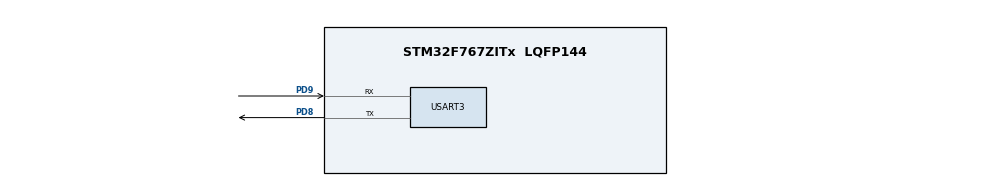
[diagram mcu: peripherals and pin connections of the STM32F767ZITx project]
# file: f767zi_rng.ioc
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CORTEX_M7.default_mode_Activation=1
Mcu.Family=STM32F7
Mcu.Name=STM32F767ZITx
Mcu.Package=LQFP144
NVIC.PriorityGroup=NVIC_PRIORITYGROUP_4
PA13.Mode=Serial_Wire
PA13.Signal=SYS_JTMS-SWDIO
PA14.Mode=Serial_Wire
PA14.Signal=SYS_JTCK-SWCLK
PD8.Mode=Asynchronous
PD8.Signal=USART3_TX
PD9.Mode=Asynchronous
PD9.Signal=USART3_RX
PH0/OSC_IN.Mode=HSE-External-Oscillator
PH0/OSC_IN.Signal=RCC_OSC_IN
PH1/OSC_OUT.Mode=HSE-External-Oscillator
PH1/OSC_OUT.Signal=RCC_OSC_OUT
ProjectManager.HeapSize=0x200
ProjectManager.StackSize=0x400
ProjectManager.TargetToolchain=STM32CubeIDE
RCC.HSE_VALUE=25000000
RCC.HSI_VALUE=16000000
RCC.LSE_VALUE=32768
RCC.PLLM=8
RCC.PLLN=96
RCC.PLLQ=4
RCC.USBFreq_Value=48000000
RCC.VCOOutputFreq_Value=192000000
USART3.VirtualMode-Asynchronous=VM_ASYNC
VP_RNG_VS_RNG.Mode=RNG_Activate
board=custom

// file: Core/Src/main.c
/* USER CODE BEGIN Header */
/**
  ******************************************************************************
  * @file           : main.c
  * @brief          : Main program body
  ******************************************************************************
  * @attention
  *
  * Copyright (c) 2025 STMicroelectronics.
  * All rights reserved.
  *
  * This software is licensed under terms that can be found in the LICENSE file
  * in the root directory of this software component.
  * If no LICENSE file comes with this software, it is provided AS-IS.
  *
  ******************************************************************************
  */
/* USER CODE END Header */
#include "main.h"

/* USER CODE BEGIN Includes */
#include <stdio.h>
#include <stdbool.h>
#include "trng.h"
/* USER CODE END Includes */

RNG_HandleTypeDef hrng;

UART_HandleTypeDef huart3;

void SystemClock_Config(void);
static void MPU_Config(void);
static void MX_GPIO_Init(void);
static void MX_USART3_UART_Init(void);
static void MX_RNG_Init(void);

/* USER CODE BEGIN 0 */

/* redirect printf to uart3
 fd == file descriptor. 1 = stdout, 2 stderr
 ptr == pointer to the data being sent
 len == length of the data (in bytes)
*/
int _write(int fd, char* ptr, int len) {
 HAL_StatusTypeDef hstatus;

 if (fd == 1 || fd == 2) {
   hstatus = HAL_UART_Transmit(&huart3, (uint8_t *) ptr, len, HAL_MAX_DELAY);
   if (hstatus == HAL_OK)
     return len;
   else
     return -1;
 }
 return -1;
}

/* USER CODE END 0 */

int main(void)
{

  /* MPU Configuration--------------------------------------------------------*/
  MPU_Config();

  /* MCU Configuration--------------------------------------------------------*/

  /* Reset of all peripherals, Initializes the Flash interface and the Systick. */
  HAL_Init();

  /* Configure the system clock */
  SystemClock_Config();

  /* Initialize all configured peripherals */
  MX_GPIO_Init();
  MX_USART3_UART_Init();
  MX_RNG_Init();
  /* USER CODE BEGIN 2 */
  printf("Starting RNG code...\r\n");
  trng_init();
  /* USER CODE END 2 */

  /* Infinite loop */
  /* USER CODE BEGIN WHILE */
  uint32_t now = 0,next_tick=1000;
  while (1)
  {
	  now = uwTick;
	  if(now >= next_tick){
		  printf("Tick %lu. Random value = %lu \r\n",now/1000,trng_get());
		  next_tick = now+1000;
	  }

  }
    /* USER CODE END WHILE */

}

void SystemClock_Config(void)
{
  RCC_OscInitTypeDef RCC_OscInitStruct = {0};
  RCC_ClkInitTypeDef RCC_ClkInitStruct = {0};

  /** Configure the main internal regulator output voltage
  */
  __HAL_RCC_PWR_CLK_ENABLE();
  __HAL_PWR_VOLTAGESCALING_CONFIG(PWR_REGULATOR_VOLTAGE_SCALE3);

  /** Initializes the RCC Oscillators according to the specified parameters
  * in the RCC_OscInitTypeDef structure.
  */
  RCC_OscInitStruct.OscillatorType = RCC_OSCILLATORTYPE_HSI;
  RCC_OscInitStruct.HSIState = RCC_HSI_ON;
  RCC_OscInitStruct.HSICalibrationValue = RCC_HSICALIBRATION_DEFAULT;
  RCC_OscInitStruct.PLL.PLLState = RCC_PLL_ON;
  RCC_OscInitStruct.PLL.PLLSource = RCC_PLLSOURCE_HSI;
  RCC_OscInitStruct.PLL.PLLM = 8;
  RCC_OscInitStruct.PLL.PLLN = 96;
  RCC_OscInitStruct.PLL.PLLP = RCC_PLLP_DIV2;
  RCC_OscInitStruct.PLL.PLLQ = 4;
  RCC_OscInitStruct.PLL.PLLR = 2;
  if (HAL_RCC_OscConfig(&RCC_OscInitStruct) != HAL_OK)
  {
    Error_Handler();
  }

  /** Initializes the CPU, AHB and APB buses clocks
  */
  RCC_ClkInitStruct.ClockType = RCC_CLOCKTYPE_HCLK|RCC_CLOCKTYPE_SYSCLK
                              |RCC_CLOCKTYPE_PCLK1|RCC_CLOCKTYPE_PCLK2;
  RCC_ClkInitStruct.SYSCLKSource = RCC_SYSCLKSOURCE_HSI;
  RCC_ClkInitStruct.AHBCLKDivider = RCC_SYSCLK_DIV1;
  RCC_ClkInitStruct.APB1CLKDivider = RCC_HCLK_DIV1;
  RCC_ClkInitStruct.APB2CLKDivider = RCC_HCLK_DIV1;

  if (HAL_RCC_ClockConfig(&RCC_ClkInitStruct, FLASH_LATENCY_0) != HAL_OK)
  {
    Error_Handler();
  }
}

static void MX_RNG_Init(void)
{

  hrng.Instance = RNG;
  if (HAL_RNG_Init(&hrng) != HAL_OK)
  {
    Error_Handler();
  }

}

static void MX_USART3_UART_Init(void)
{

  huart3.Instance = USART3;
  huart3.Init.BaudRate = 115200;
  huart3.Init.WordLength = UART_WORDLENGTH_8B;
  huart3.Init.StopBits = UART_STOPBITS_1;
  huart3.Init.Parity = UART_PARITY_NONE;
  huart3.Init.Mode = UART_MODE_TX_RX;
  huart3.Init.HwFlowCtl = UART_HWCONTROL_NONE;
  huart3.Init.OverSampling = UART_OVERSAMPLING_16;
  huart3.Init.OneBitSampling = UART_ONE_BIT_SAMPLE_DISABLE;
  huart3.AdvancedInit.AdvFeatureInit = UART_ADVFEATURE_NO_INIT;
  if (HAL_UART_Init(&huart3) != HAL_OK)
  {
    Error_Handler();
  }

}

static void MX_GPIO_Init(void)
{

  /* GPIO Ports Clock Enable */
  __HAL_RCC_GPIOH_CLK_ENABLE();
  __HAL_RCC_GPIOD_CLK_ENABLE();
  __HAL_RCC_GPIOA_CLK_ENABLE();

}

 /* MPU Configuration */

void MPU_Config(void)
{
  MPU_Region_InitTypeDef MPU_InitStruct = {0};

  /* Disables the MPU */
  HAL_MPU_Disable();

  /** Initializes and configures the Region and the memory to be protected
  */
  MPU_InitStruct.Enable = MPU_REGION_ENABLE;
  MPU_InitStruct.Number = MPU_REGION_NUMBER0;
  MPU_InitStruct.BaseAddress = 0x0;
  MPU_InitStruct.Size = MPU_REGION_SIZE_4GB;
  MPU_InitStruct.SubRegionDisable = 0x87;
  MPU_InitStruct.TypeExtField = MPU_TEX_LEVEL0;
  MPU_InitStruct.AccessPermission = MPU_REGION_NO_ACCESS;
  MPU_InitStruct.DisableExec = MPU_INSTRUCTION_ACCESS_DISABLE;
  MPU_InitStruct.IsShareable = MPU_ACCESS_SHAREABLE;
  MPU_InitStruct.IsCacheable = MPU_ACCESS_NOT_CACHEABLE;
  MPU_InitStruct.IsBufferable = MPU_ACCESS_NOT_BUFFERABLE;

  HAL_MPU_ConfigRegion(&MPU_InitStruct);
  /* Enables the MPU */
  HAL_MPU_Enable(MPU_PRIVILEGED_DEFAULT);

}

void Error_Handler(void)
{
  __disable_irq();
  while (1)
  {
  }
}
